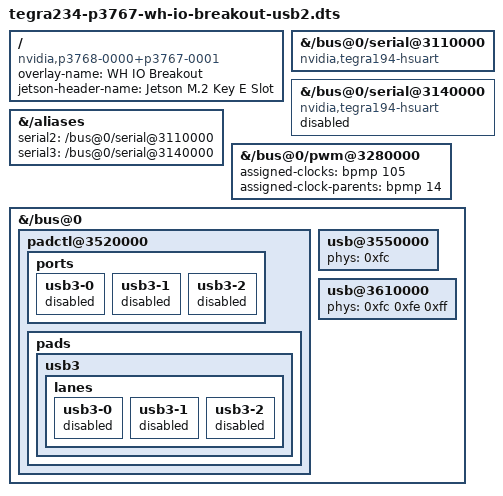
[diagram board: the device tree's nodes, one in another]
/dts-v1/;
/plugin/;

/ {
    overlay-name = "WH IO Breakout";
    jetson-header-name = "Jetson M.2 Key E Slot";
    compatible = "nvidia,p3768-0000+p3767-0001", "nvidia,p3767-0001", "nvidia,tegra234";

    fragment@0 {
        target-path = "/bus@0/serial@3110000";

        __overlay__ {
            compatible = "nvidia,tegra194-hsuart";
            reset-names = "serial";
            status = "okay";
        };
    };

    fragment@1 {
        target-path = "/bus@0/serial@3140000";

        __overlay__ {
            compatible = "nvidia,tegra194-hsuart";
            status = "disabled";
        };
    };

    fragment@2 {
        target-path = "/aliases";

        __overlay__ {
            serial2 = "/bus@0/serial@3110000";
            serial3 = "/bus@0/serial@3140000";
        };
    };

    fragment@3 {
        target-path = "/bus@0/pwm@3280000";

        __overlay__ {
            assigned-clocks = <&bpmp 105>;
            assigned-clock-parents = <&bpmp 14>;
        };
    };

    /*
     * Disable USB3/SuperSpeed so everything (RealSense D4xx included) enumerates
     * at USB2 HighSpeed.
     *
     * phys are the base DTB's usb2-0/1/2 lane phandles, hardcoded because those
     * lanes carry no label in the base __symbols__. Phandles are assigned at
     * base-tree compile time, so re-verify after every BSP bump.
     */
    fragment@4 {
        target-path = "/bus@0";

        __overlay__ {
            padctl@3520000 {
                ports {
                    usb3-0 { status = "disabled"; };
                    usb3-1 { status = "disabled"; };
                    usb3-2 { status = "disabled"; };
                };

                pads {
                    usb3 {
                        lanes {
                            usb3-0 { status = "disabled"; };
                            usb3-1 { status = "disabled"; };
                            usb3-2 { status = "disabled"; };
                        };
                    };
                };
            };

            usb@3550000 {
                phys = <0xfc>;
                phy-names = "usb2-0";
            };

            usb@3610000 {
                phys = <0xfc 0xfe 0xff>;
                phy-names = "usb2-0", "usb2-1", "usb2-2";
            };
        };
    };
};
